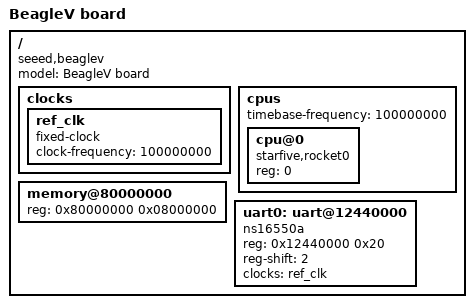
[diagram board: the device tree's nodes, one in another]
// SPDX-License-Identifier: GPL-2.0-only

/dts-v1/;

/ {
	model = "BeagleV board";
	compatible = "seeed,beaglev";

	#address-cells = <1>;
	#size-cells = <1>;

	clocks {
		ref_clk: ref_clk {
			#clock-cells = <0>;
			compatible = "fixed-clock";
			clock-frequency = <100000000>;
		};
	};

	cpus {
		#address-cells = <1>;
		#size-cells = <0>;

		timebase-frequency = <100000000>;

		cpu@0 {
			device_type = "cpu";
			compatible = "starfive,rocket0", "riscv";
			reg = <0>;
		};
	};

	memory@80000000 {
		device_type = "memory";
		reg = <0x80000000 0x08000000>;
	};

	uart0: uart@12440000 {
		compatible = "ns16550a";
		reg = <0x12440000 0x20>;
		reg-shift = <2>;
		clocks = <&ref_clk>;
	};

};
